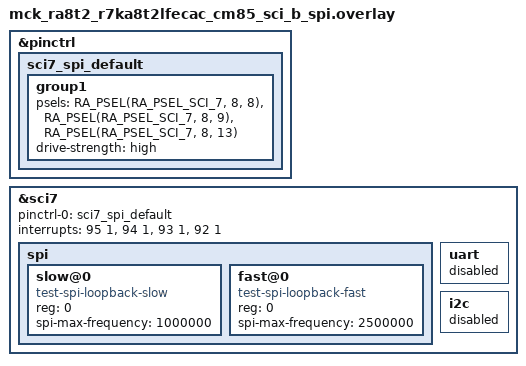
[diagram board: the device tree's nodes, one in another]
/*
 * Copyright (c) 2025 Renesas Electronics Corporation
 * SPDX-License-Identifier: Apache-2.0
 */

&pinctrl {
	sci7_spi_default: sci7_spi_default {
		group1 {
			/* MISO7 MOSI7 SCK7 */
			psels = <RA_PSEL(RA_PSEL_SCI_7, 8, 8)>,
				<RA_PSEL(RA_PSEL_SCI_7, 8, 9)>,
				<RA_PSEL(RA_PSEL_SCI_7, 8, 13)>;
			drive-strength = "high";
		};
	};
};

&sci7 {
	pinctrl-0 = <&sci7_spi_default>;
	pinctrl-names = "default";
	interrupts = <95 1>, <94 1>, <93 1>, <92 1>;
	interrupt-names = "rxi", "txi", "tei", "eri";
	status = "okay";

	spi {
		status = "okay";

		slow@0 {
			compatible = "test-spi-loopback-slow";
			reg = <0>;
			spi-max-frequency = <1000000>;
		};

		fast@0 {
			compatible = "test-spi-loopback-fast";
			reg = <0>;
			spi-max-frequency = <2500000>;
		};
	};

	uart {
		status = "disabled";
	};

	i2c {
		status = "disabled";
	};
};
